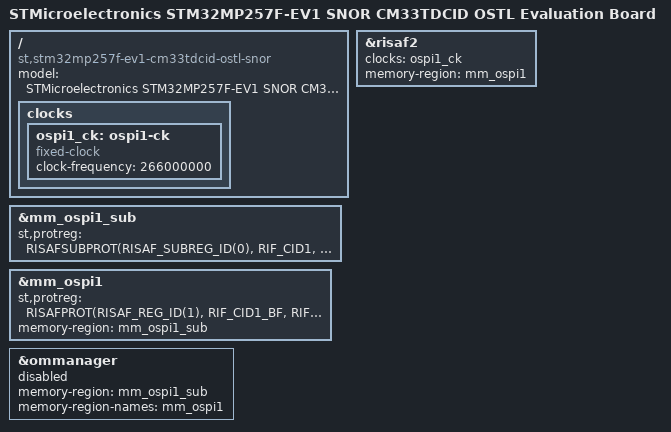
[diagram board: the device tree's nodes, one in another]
// SPDX-License-Identifier: (GPL-2.0-only OR BSD-3-Clause)
/*
 * Copyright (C) STMicroelectronics 2023 - All Rights Reserved
 * Author: Alexandre Torgue <alexandre.torgue@foss.st.com> for STMicroelectronics.
 */

/dts-v1/;

#include "stm32mp257f-ev1-cm33tdcid-ostl.dts"
#include "stm32mp257f-ev1-cm33tdcid-ostl-resmem-snor.dtsi"

/ {
	model = "STMicroelectronics STM32MP257F-EV1 SNOR CM33TDCID OSTL Evaluation Board";
	compatible = "st,stm32mp257f-ev1-cm33tdcid-ostl-snor", "st,stm32mp257f-ev1", "st,stm32mp257";

	clocks {
		ospi1_ck: ospi1-ck {
			compatible = "fixed-clock";
			#clock-cells = <0>;
			clock-frequency = <266000000>;
		};
	};
};

&risaf2 {
	clocks = <&ospi1_ck>;
};

&mm_ospi1_sub {
	st,protreg = <RISAFSUBPROT(RISAF_SUBREG_ID(0), RIF_CID1, RIF_DCEN_EN, RIF_RDEN_EN, RIF_WREN_EN, RIF_CID1, RIF_PRIV, RIF_NSEC, RIF_SREN_EN, RIF_RLOCK_DIS)>;
};

&mm_ospi1 {
	st,protreg = <RISAFPROT(RISAF_REG_ID(1), RIF_CID1_BF, RIF_CID1_BF, RIF_CID1_BF, RIF_SEC, RIF_ENC_DIS, RIF_BREN_EN)>;
	memory-region= <&mm_ospi1_sub>;
};

&risaf2 {
	memory-region= <&mm_ospi1>;
	status = "okay";
};

&ommanager {
	memory-region = <&mm_ospi1_sub>;
	memory-region-names = "mm_ospi1";
	status = "disabled";
};
